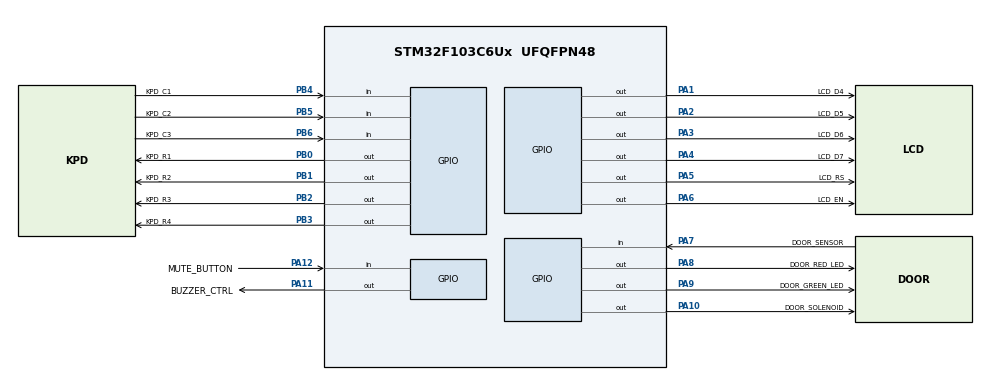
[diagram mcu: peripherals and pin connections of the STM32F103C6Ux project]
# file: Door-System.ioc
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Mcu.Family=STM32F1
Mcu.Name=STM32F103C6Ux
Mcu.Package=UFQFPN48
NVIC.PriorityGroup=NVIC_PRIORITYGROUP_4
NVIC.TIM2_IRQn=true\:0\:0\:false\:false\:true\:true\:true
PA1.GPIO_Label=LCD_D4
PA1.Signal=GPIO_Output
PA10.GPIO_Label=DOOR_SOLENOID
PA10.Signal=GPIO_Output
PA11.GPIO_Label=BUZZER_CTRL
PA11.GPIO_PuPd=GPIO_PULLDOWN
PA11.Signal=GPIO_Output
PA12.GPIO_Label=MUTE_BUTTON
PA12.GPIO_PuPd=GPIO_PULLDOWN
PA12.Signal=GPIO_Input
PA13.Mode=Serial_Wire
PA13.Signal=SYS_JTMS-SWDIO
PA14.Mode=Serial_Wire
PA14.Signal=SYS_JTCK-SWCLK
PA2.GPIO_Label=LCD_D5
PA2.Signal=GPIO_Output
PA3.GPIO_Label=LCD_D6
PA3.Signal=GPIO_Output
PA4.GPIO_Label=LCD_D7
PA4.Signal=GPIO_Output
PA5.GPIO_Label=LCD_RS
PA5.Signal=GPIO_Output
PA6.GPIO_Label=LCD_EN
PA6.Signal=GPIO_Output
PA7.GPIO_Label=DOOR_SENSOR
PA7.Signal=GPIO_Input
PA8.GPIO_Label=DOOR_RED_LED
PA8.Signal=GPIO_Output
PA9.GPIO_Label=DOOR_GREEN_LED
PA9.Signal=GPIO_Output
PB0.GPIO_Label=KPD_R1
PB0.Signal=GPIO_Output
PB1.GPIO_Label=KPD_R2
PB1.Signal=GPIO_Output
PB2.GPIO_Label=KPD_R3
PB2.Signal=GPIO_Output
PB3.GPIO_Label=KPD_R4
PB3.Signal=GPIO_Output
PB4.GPIO_Label=KPD_C1
PB4.GPIO_PuPd=GPIO_PULLUP
PB4.Signal=GPIO_Input
PB5.GPIO_Label=KPD_C2
PB5.GPIO_PuPd=GPIO_PULLUP
PB5.Signal=GPIO_Input
PB6.GPIO_Label=KPD_C3
PB6.GPIO_PuPd=GPIO_PULLUP
PB6.Signal=GPIO_Input
ProjectManager.HeapSize=0x200
ProjectManager.StackSize=0x400
ProjectManager.TargetToolchain=STM32CubeIDE
RCC.APB1Freq_Value=8000000
RCC.APB2Freq_Value=8000000
TIM2.Period=9
TIM2.Prescaler=7999
VP_TIM2_VS_ClockSourceINT.Mode=Internal
board=custom

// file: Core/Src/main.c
/* USER CODE BEGIN Header */
/*
 *
 ******************************************************************************
 */
/* USER CODE END Header */
#include "main.h"

/* USER CODE BEGIN Includes */
#include <string.h>
#include <stdio.h>
#include "global.h"
/* USER CODE END Includes */

TIM_HandleTypeDef htim2;

/* USER CODE BEGIN PV */
/* System state variables */

/* USER CODE END PV */

void SystemClock_Config(void);
static void MX_GPIO_Init(void);
static void MX_TIM2_Init(void);
/* USER CODE BEGIN PFP */
/* Application Functions */
/* USER CODE END PFP */

int main(void)
{

  /* MCU Configuration--------------------------------------------------------*/

  /* Reset of all peripherals, Initializes the Flash interface and the Systick. */
  HAL_Init();

  /* Configure the system clock */
  SystemClock_Config();

  /* Initialize all configured peripherals */
  MX_GPIO_Init();
  MX_TIM2_Init();
  /* USER CODE BEGIN 2 */
	HAL_TIM_Base_Start_IT(&htim2);

	/* Initialize custom drivers */
	LCD_Init();

	// Initialize subsystems
	door_init();
	password_init();

  /* USER CODE END 2 */

  /* Infinite loop */
  /* USER CODE BEGIN WHILE */
	while (1) {
		password_fsm_run();  // Handle keypad + password + lockout
		door_fsm_run();      // Handle solenoid + door sensor + LEDs
		Buzzer_Run();        // Handle buzzer alarm + mute button
    /* USER CODE END WHILE */

	}
}

void SystemClock_Config(void)
{
  RCC_OscInitTypeDef RCC_OscInitStruct = {0};
  RCC_ClkInitTypeDef RCC_ClkInitStruct = {0};

  /** Initializes the RCC Oscillators according to the specified parameters
  * in the RCC_OscInitTypeDef structure.
  */
  RCC_OscInitStruct.OscillatorType = RCC_OSCILLATORTYPE_HSI;
  RCC_OscInitStruct.HSIState = RCC_HSI_ON;
  RCC_OscInitStruct.HSICalibrationValue = RCC_HSICALIBRATION_DEFAULT;
  RCC_OscInitStruct.PLL.PLLState = RCC_PLL_NONE;
  if (HAL_RCC_OscConfig(&RCC_OscInitStruct) != HAL_OK)
  {
    Error_Handler();
  }
  /** Initializes the CPU, AHB and APB buses clocks
  */
  RCC_ClkInitStruct.ClockType = RCC_CLOCKTYPE_HCLK|RCC_CLOCKTYPE_SYSCLK
                              |RCC_CLOCKTYPE_PCLK1|RCC_CLOCKTYPE_PCLK2;
  RCC_ClkInitStruct.SYSCLKSource = RCC_SYSCLKSOURCE_HSI;
  RCC_ClkInitStruct.AHBCLKDivider = RCC_SYSCLK_DIV1;
  RCC_ClkInitStruct.APB1CLKDivider = RCC_HCLK_DIV1;
  RCC_ClkInitStruct.APB2CLKDivider = RCC_HCLK_DIV1;

  if (HAL_RCC_ClockConfig(&RCC_ClkInitStruct, FLASH_LATENCY_0) != HAL_OK)
  {
    Error_Handler();
  }
}

static void MX_TIM2_Init(void)
{

  TIM_ClockConfigTypeDef sClockSourceConfig = {0};
  TIM_MasterConfigTypeDef sMasterConfig = {0};

  htim2.Instance = TIM2;
  htim2.Init.Prescaler = 7999;
  htim2.Init.CounterMode = TIM_COUNTERMODE_UP;
  htim2.Init.Period = 9;
  htim2.Init.ClockDivision = TIM_CLOCKDIVISION_DIV1;
  htim2.Init.AutoReloadPreload = TIM_AUTORELOAD_PRELOAD_DISABLE;
  if (HAL_TIM_Base_Init(&htim2) != HAL_OK)
  {
    Error_Handler();
  }
  sClockSourceConfig.ClockSource = TIM_CLOCKSOURCE_INTERNAL;
  if (HAL_TIM_ConfigClockSource(&htim2, &sClockSourceConfig) != HAL_OK)
  {
    Error_Handler();
  }
  sMasterConfig.MasterOutputTrigger = TIM_TRGO_RESET;
  sMasterConfig.MasterSlaveMode = TIM_MASTERSLAVEMODE_DISABLE;
  if (HAL_TIMEx_MasterConfigSynchronization(&htim2, &sMasterConfig) != HAL_OK)
  {
    Error_Handler();
  }

}

static void MX_GPIO_Init(void)
{
  GPIO_InitTypeDef GPIO_InitStruct = {0};

  /* GPIO Ports Clock Enable */
  __HAL_RCC_GPIOA_CLK_ENABLE();
  __HAL_RCC_GPIOB_CLK_ENABLE();

  /*Configure GPIO pin Output Level */
  HAL_GPIO_WritePin(GPIOA, LCD_D4_Pin|LCD_D5_Pin|LCD_D6_Pin|LCD_D7_Pin
                          |LCD_RS_Pin|LCD_EN_Pin|DOOR_RED_LED_Pin|DOOR_GREEN_LED_Pin
                          |DOOR_SOLENOID_Pin|BUZZER_CTRL_Pin, GPIO_PIN_RESET);

  /*Configure GPIO pin Output Level */
  HAL_GPIO_WritePin(GPIOB, KPD_R1_Pin|KPD_R2_Pin|KPD_R3_Pin|KPD_R4_Pin, GPIO_PIN_SET);

  /*Configure GPIO pins : LCD_D4_Pin LCD_D5_Pin LCD_D6_Pin LCD_D7_Pin
                           LCD_RS_Pin LCD_EN_Pin DOOR_RED_LED_Pin DOOR_GREEN_LED_Pin
                           DOOR_SOLENOID_Pin */
  GPIO_InitStruct.Pin = LCD_D4_Pin|LCD_D5_Pin|LCD_D6_Pin|LCD_D7_Pin
                          |LCD_RS_Pin|LCD_EN_Pin|DOOR_RED_LED_Pin|DOOR_GREEN_LED_Pin
                          |DOOR_SOLENOID_Pin;
  GPIO_InitStruct.Mode = GPIO_MODE_OUTPUT_PP;
  GPIO_InitStruct.Pull = GPIO_NOPULL;
  GPIO_InitStruct.Speed = GPIO_SPEED_FREQ_LOW;
  HAL_GPIO_Init(GPIOA, &GPIO_InitStruct);

  /*Configure GPIO pin : DOOR_SENSOR_Pin */
  GPIO_InitStruct.Pin = DOOR_SENSOR_Pin;
  GPIO_InitStruct.Mode = GPIO_MODE_INPUT;
  GPIO_InitStruct.Pull = GPIO_NOPULL;
  HAL_GPIO_Init(DOOR_SENSOR_GPIO_Port, &GPIO_InitStruct);

  /*Configure GPIO pins : KPD_R1_Pin KPD_R2_Pin KPD_R3_Pin KPD_R4_Pin */
  GPIO_InitStruct.Pin = KPD_R1_Pin|KPD_R2_Pin|KPD_R3_Pin|KPD_R4_Pin;
  GPIO_InitStruct.Mode = GPIO_MODE_OUTPUT_PP;
  GPIO_InitStruct.Pull = GPIO_NOPULL;
  GPIO_InitStruct.Speed = GPIO_SPEED_FREQ_LOW;
  HAL_GPIO_Init(GPIOB, &GPIO_InitStruct);

  /*Configure GPIO pin : BUZZER_CTRL_Pin */
  GPIO_InitStruct.Pin = BUZZER_CTRL_Pin;
  GPIO_InitStruct.Mode = GPIO_MODE_OUTPUT_PP;
  GPIO_InitStruct.Pull = GPIO_PULLDOWN;
  GPIO_InitStruct.Speed = GPIO_SPEED_FREQ_LOW;
  HAL_GPIO_Init(BUZZER_CTRL_GPIO_Port, &GPIO_InitStruct);

  /*Configure GPIO pin : MUTE_BUTTON_Pin */
  GPIO_InitStruct.Pin = MUTE_BUTTON_Pin;
  GPIO_InitStruct.Mode = GPIO_MODE_INPUT;
  GPIO_InitStruct.Pull = GPIO_PULLDOWN;
  HAL_GPIO_Init(MUTE_BUTTON_GPIO_Port, &GPIO_InitStruct);

  /*Configure GPIO pins : KPD_C1_Pin KPD_C2_Pin KPD_C3_Pin */
  GPIO_InitStruct.Pin = KPD_C1_Pin|KPD_C2_Pin|KPD_C3_Pin;
  GPIO_InitStruct.Mode = GPIO_MODE_INPUT;
  GPIO_InitStruct.Pull = GPIO_PULLUP;
  HAL_GPIO_Init(GPIOB, &GPIO_InitStruct);

}

/* USER CODE BEGIN 4 */
void HAL_TIM_PeriodElapsedCallback(TIM_HandleTypeDef *htim) {

	timerRun();

}
/* USER CODE END 4 */

void Error_Handler(void)
{
	__disable_irq();
	while (1) {
	}
}

/************************ (C) COPYRIGHT STMicroelectronics *****END OF FILE****/
